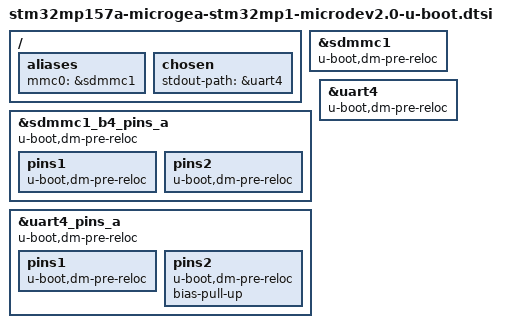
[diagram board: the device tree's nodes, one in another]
// SPDX-License-Identifier: (GPL-2.0+ OR BSD-3-Clause)
/*
 * Copyright (C) STMicroelectronics 2019 - All Rights Reserved
 * Copyright (c) 2020 Amarula Solutions(India)
 * Author: Jagan Teki <jagan@amarulasolutions.com>
 */

#include "stm32mp157a-microgea-stm32mp1-u-boot.dtsi"

/{
	aliases {
		mmc0 = &sdmmc1;
	};

	chosen {
		stdout-path = &uart4;
	};
};

&sdmmc1 {
	u-boot,dm-pre-reloc;
};

&sdmmc1_b4_pins_a {
	u-boot,dm-pre-reloc;

	pins1 {
		u-boot,dm-pre-reloc;
	};

	pins2 {
		u-boot,dm-pre-reloc;
	};
};

&uart4 {
	u-boot,dm-pre-reloc;
};

&uart4_pins_a {
	u-boot,dm-pre-reloc;

	pins1 {
		u-boot,dm-pre-reloc;
	};

	pins2 {
		u-boot,dm-pre-reloc;
		bias-pull-up;
	};
};
